# A31G324 register map
Vendor: ABOV Semiconductor Co., Ltd.; Series: A31G324; File version: 1.0
CPU: CM0PLUS r0p1, little endian, no MPU, no FPU, VTOR, 2 interrupt priority bits
Registers are 32-bit, read-write, reset 0x0 unless marked. A register's access mark holds for its fields unless they carry their own. Offsets are from the block's base; [hi:lo] are bit positions; {n}, {i} and the like mark numbered series.

## SCU — System Control Unit
Base 0x40000000
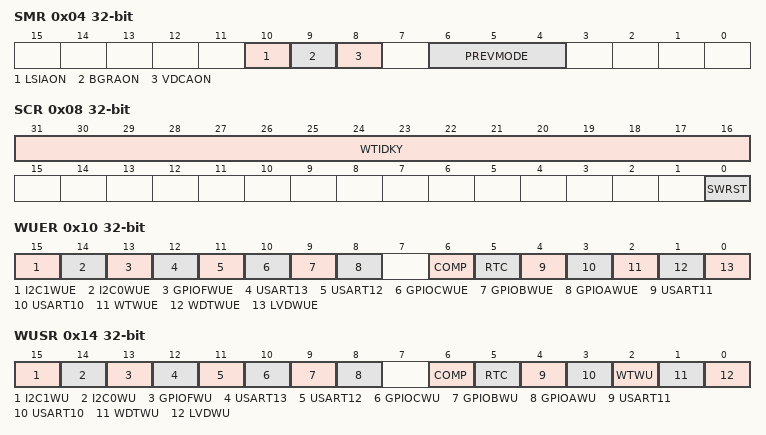
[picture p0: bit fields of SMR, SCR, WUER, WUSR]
0x04 SMR — System Mode Register
  [10] LSIAON — LSI Always on select bit in power down mode 0: LSI is automatically off entering power down mode 1: LSI isn't automatically off entering power down mode
  [9] BGRAON — BGR Always on select bit in power down mode 0: BGR is automatically off entering power down mode 1: BGR isn't automatically off entering power down mode
  [8] VDCAON — VDC Always on select bit in power down mode 0: VDC is automatically off entering power down mode 1: VDC isn't automatically off entering power down mdoe
  [6:4] PREVMODE — Previous operating mode before current reset event
0x08 SCR — System Control Register
  [31:16] WTIDKY wo — On writes, write 0x9EB3 to these bits, otherwise the write is ignored.
  [0] SWRST — Internal soft reset activation bit (check RSER[4] for reset)
0x10 WUER — Wake up source enable register
  [15] I2C1WUE — Enable wakeup source of I2C1 change event
  [14] I2C0WUE — Enable wakeup source of I2C0 change event
  [13] GPIOFWUE — Enable wakeup source of GPIOF port pin change event
  [12] USART13 — Enable wakeup source of USART13 change event
  [11] USART12 — Enable wakeup source of USART12 change event
  [10] GPIOCWUE — Enable wakeup source of GPIOC port pin change event
  [9] GPIOBWUE — Enable wakeup source of GPIOB port pin change event
  [8] GPIOAWUE — Enable wakeup source of GPIOA port pin change event
  [6] COMP — Enable wakeup source of COMP change event
  [5] RTC — Enable wakeup source of RTC change event
  [4] USART11 — Enable wakeup source of USART11 change event
  [3] USART10 — Enable wakeup source of USART10 change event
  [2] WTWUE — Enable wakeup source of watch timer event
  [1] WDTWUE — Enable wakeup source of watchdog timer event
  [0] LVDWUE — Enable wakeup source of LVD event
0x14 WUSR — Wake up source status register
  [15] I2C1WU ro — Status of wakeup source of I2C1 change event
  [14] I2C0WU ro — Status of wakeup source of I2C0 change event
  [13] GPIOFWU ro — Status of wakeup source of GPIOF port pin change event
  [12] USART13 ro — Status of wakeup source of USART13 change event
  [11] USART12 ro — Status of wakeup source of USART12 change event
  [10] GPIOCWU ro — Status of wakeup source of GPIOC port pin change event
  [9] GPIOBWU ro — Status of wakeup source of GPIOB port pin change event
  [8] GPIOAWU ro — Status of wakeup source of GPIOA port pin change event
  [6] COMP ro — Status of wakeup source of COMP change event
  [5] RTC ro — Status of wakeup source of RTC change event
  [4] USART11 ro — Status of wakeup source of USART11 change event
  [3] USART10 ro — Status of wakeup source of USART10 change event
  [2] WTWU ro — Status of wakeup source of watch timer event
  [1] WDTWU ro — Status of wakeup source of watchdog timer event
  [0] LVDWU ro — Status of wakeup source of LVD event
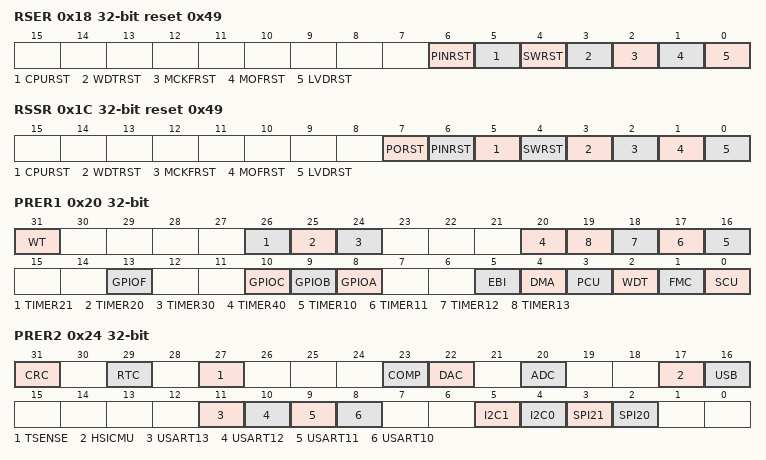
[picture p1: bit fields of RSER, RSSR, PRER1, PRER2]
0x18 RSER reset 0x49 — Reset source enable register
  [6] PINRST — External pin reset enable bit
  [5] CPURST — CPU request reset enable bit
  [4] SWRST — Software reset enable bit
  [3] WDTRST — Watchdog Timer reset enable bit
  [2] MCKFRST — MCLK Clock fail reset enable bit
  [1] MOFRST — MOSC Clock fail reset enable bit
  [0] LVDRST — LVD reset enable bit
0x1C RSSR reset 0x49 — Reset source status register
  [7] PORST — Power on reset status bit
  [6] PINRST — External pin reset status bit
  [5] CPURST — CPU request reset status bit
  [4] SWRST — Software reset status bit
  [3] WDTRST — Watchdog Timer reset status bit
  [2] MCKFRST — MCLK Clock fail reset status bit
  [1] MOFRST — MOSC Clock fail reset status bit
  [0] LVDRST — LVD reset status bit
0x20 PRER1 — Peripheral reset enable register 1
  [31] WT — WT reset mask
  [26] TIMER21 — TIMER21 reset mask
  [25] TIMER20 — TIMER20 reset mask
  [24] TIMER30 — TIMER30 reset mask
  [20] TIMER40 — TIMER40 reset mask
  [n+6] TIMER{n} (n=10..13) — TIMER{n} reset mask
  [13] GPIOF — GPIOF reset mask
  [10] GPIOC — GPIOC reset mask
  [9] GPIOB — GPIOB reset mask
  [8] GPIOA — GPIOA reset mask
  [5] EBI — EBI reset mask
  [4] DMA — DMA reset mask
  [3] PCU — PCU reset mask
  [2] WDT — WDT reset mask
  [1] FMC — FMC reset mask
  [0] SCU — SCU reset mask
0x24 PRER2 — Peripheral reset enable register 2
  [31] CRC — CRC reset mask
  [29] RTC — RTC reset mask
  [27] TSENSE — TSENSE reset mask
  [23] COMP — COMP reset mask
  [22] DAC — DAC reset mask
  [20] ADC — ADC reset mask
  [17] HSICMU — HSICMU reset mask
  [16] USB — USB reset mask
  [11] USART13 — USART13 reset mask
  [10] USART12 — UASRT12 reset mask
  [9] USART11 — USART11 reset mask
  [8] USART10 — USART10 reset mask
  [5] I2C1 — I2C1 reset mask
  [4] I2C0 — I2C0 reset mask
  [3] SPI21 — SPI21 reset mask
  [2] SPI20 — SPI20 reset mask
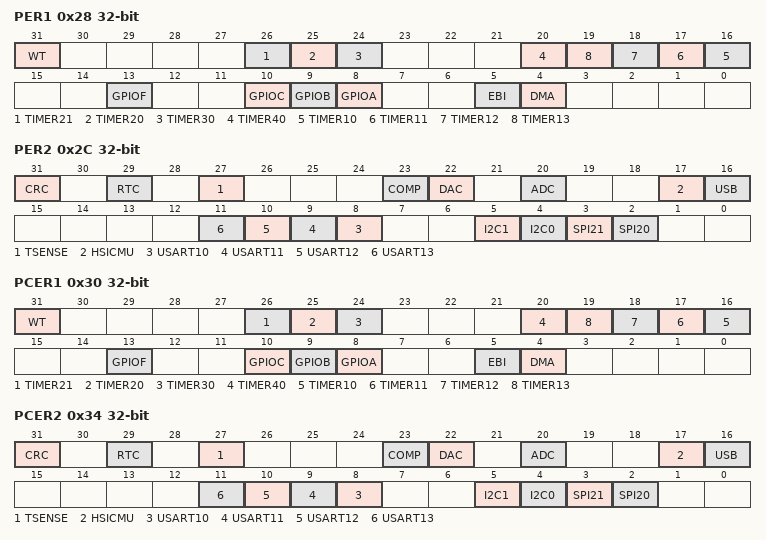
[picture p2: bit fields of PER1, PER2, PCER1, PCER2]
0x28 PER1 — Peripheral enable register 1
  [31] WT — WT function enable
  [26] TIMER21 — TIMER21 function enable
  [25] TIMER20 — TIMER20 function enable
  [24] TIMER30 — TIMER30 function enable
  [20] TIMER40 — TIMER40 function enable
  [n+6] TIMER{n} (n=10..13) — TIMER{n} function enable
  [13] GPIOF — GPIOF function enable
  [10] GPIOC — GPIOC function enable
  [9] GPIOB — GPIOB function enable
  [8] GPIOA — GPIOA function enable
  [5] EBI — EBI function enable
  [4] DMA — DMA function enable
0x2C PER2 — Peripheral enable register 2
  [31] CRC — CRC function enable
  [29] RTC — RTC function enable
  [27] TSENSE — TSENSE function enable
  [23] COMP — COMP function enable
  [22] DAC — DAC function enable
  [20] ADC — ADC function enable
  [17] HSICMU — HSICMU function enable
  [16] USB — USB function enable
  [n-2] USART{n} (n=10..13) — USART{n} function enable
  [5] I2C1 — I2C1 function enable
  [4] I2C0 — I2C0 function enable
  [3] SPI21 — SPI21 function enable
  [2] SPI20 — SPI20 function enable
0x30 PCER1 — Peripheral clock enable register 1
  [31] WT — WT clock enable
  [26] TIMER21 — TIMER21 clock enable
  [25] TIMER20 — TIMER20 clock enable
  [24] TIMER30 — TIMER30 clock enable
  [20] TIMER40 — TIMER40 clock enable
  [n+6] TIMER{n} (n=10..13) — TIMER{n} clock enable
  [13] GPIOF — GPIOF clock enable
  [10] GPIOC — GPIOC clock enable
  [9] GPIOB — GPIOB clock enable
  [8] GPIOA — GPIOA clock enable
  [5] EBI — EBI clock enable
  [4] DMA — DMA clock enable
0x34 PCER2 — Peripheral clock enable register 2
  [31] CRC — CRC clock enable
  [29] RTC — RTC clock enable
  [27] TSENSE — TSENSE clock enable
  [23] COMP — COMP clock enable
  [22] DAC — DAC clock enable
  [20] ADC — ADC clock enable
  [17] HSICMU — HSICMU clock enable
  [16] USB — USB clock enable
  [n-2] USART{n} (n=10..13) — USART{n} clock enable
  [5] I2C1 — I2C1 clock enable
  [4] I2C0 — I2C0 clock enable
  [3] SPI21 — SPI21 clock enable
  [2] SPI20 — SPI20 clock enable
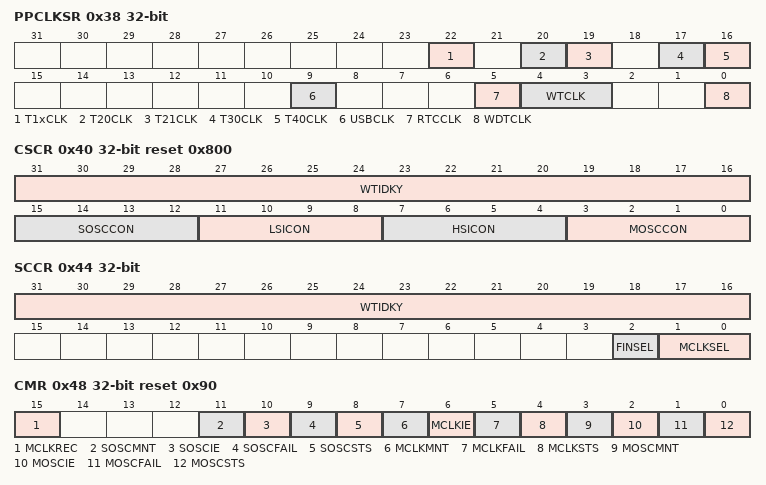
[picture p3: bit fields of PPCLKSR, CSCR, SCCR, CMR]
0x38 PPCLKSR — Peripheral clock selection register
  [22] T1xCLK — Timer 1x Clock Selection bit
  [20] T20CLK — Timer 20 Clock Selection bit
  [19] T21CLK — Timer 21 Clock Selection bit
  [17] T30CLK — Timer 30 Clock Selection bit
  [16] T40CLK — Timer 40 Clock Selection bit
  [9] USBCLK — USB Clock Selection bit
  [5] RTCCLK — RTC Clock Selection bit
  [4:3] WTCLK — Watch Timer Clock Selection bit Note) These bits should be changed during the WTEN bit of watch timer control register (WTCR) is "0b"
  [0] WDTCLK — Watch-dog Timer Clock Selection bit
0x40 CSCR reset 0x800 — Clock Source Control register
  [31:16] WTIDKY wo — On writes, write 0xA507 to these bits, otherwise the write is ignored.
  [15:12] SOSCCON — External crystal sub oscillator control
  [11:8] LSICON — Low speed internal oscillator control
  [7:4] HSICON — High speed internal oscillator control
  [3:0] MOSCCON — External crystal main oscillator control
0x44 SCCR — System Clock Control register
  [31:16] WTIDKY wo — On writes, write 0x570A to these bits, otherwise the write is ignored.
  [2] FINSEL — PLL input source FIN select register
  [1:0] MCLKSEL — System clock select register
0x48 CMR reset 0x90 — Clock Monitoring register
  [15] MCLKREC — MCLK fail auto recovery
  [11] SOSCMNT — External sub oscillator monitoring enable
  [10] SOSCIE — External sub oscillator fail interrupt enable
  [9] SOSCFAIL — External sub oscillator fail interrupt
  [8] SOSCSTS — External sub oscillator status
  [7] MCLKMNT — MCLK monitoring enable
  [6] MCLKIE — MCLK fail interrupt enable
  [5] MCLKFAIL — MCLK fail interrupt
  [4] MCLKSTS — MCLK clock status
  [3] MOSCMNT — External main oscillator monitoring enable
  [2] MOSCIE — External main oscillator fail interrupt enable
  [1] MOSCFAIL — External main oscillator fail interrupt
  [0] MOSCSTS — External main oscillator status
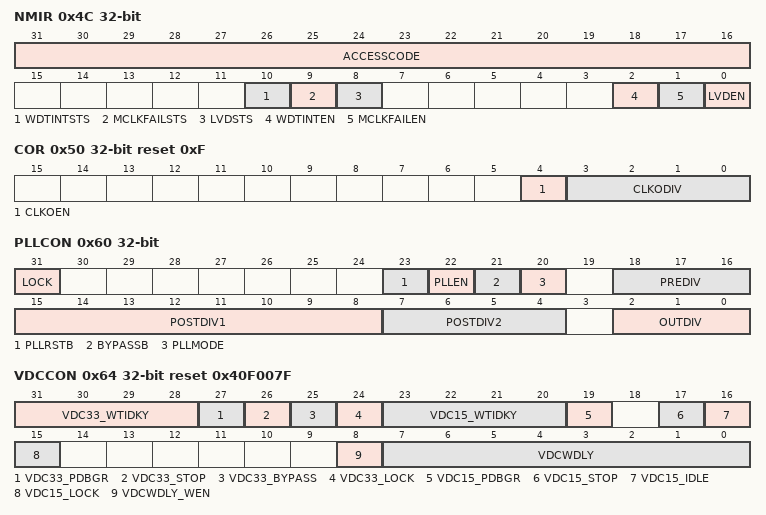
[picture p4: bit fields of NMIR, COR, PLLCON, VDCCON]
0x4C NMIR — NMI control register
  [31:16] ACCESSCODE wo — This field enables writing access to this register. Writing 0xA32C is to enable writing.
  [10] WDTINTSTS ro — WDT Interrupt condition status bit This bit can't invoke NMI interrupt without enable bit
  [9] MCLKFAILSTS ro — MCLK Fail condition status bit This bit can't invoke NMI interrupt without enable bit
  [8] LVDSTS ro — LVD condition status bit This bit can't invoke NMI interrupt without enable bit
  [2] WDTINTEN — WDT Interrupt condition enable for NMI interrupt
  [1] MCLKFAILEN — MCLK Fail condition enable for NMI interrupt
  [0] LVDEN — LVD Fail condition enable for NMI interrupt
0x50 COR reset 0xF — Clock Output Control register
  [4] CLKOEN — Clock output enable
  [3:0] CLKODIV — Clock output divider value CLKO=MCLK (CLKODIV=0) CLKO=MCLK/2(CLKODIV+1) (CLKODIV > 0)
0x60 PLLCON — PLL Control register
  [31] LOCK — LOCK status
  [23] PLLRSTB — PLL reset
  [22] PLLEN — PLL enable
  [21] BYPASSB — FIN bypass
  [20] PLLMODE — PLL VCO mode
  [18:16] PREDIV — FIN predivider FIN divided by (PREDIV + 1), (FIN/1 ~ FIN/8)
  [15:8] POSTDIV1 — Feedback control 1 (N1) N1 = POSTDIV1 + 1
  [7:4] POSTDIV2 — Feedback control 1 (N2) N2 = POSTDIV2 + 1
  [2:0] OUTDIV — output divider control (P) P = OUTDIV + 1
0x64 VDCCON reset 0x40F007F — VDC Control register
  [31:28] VDC33_WTIDKY wo — VDC33 Write Identification Key On writes, write 0xA to these bits, otherwise the write is ignored.
  [27] VDC33_PDBGR — VDC33 BGR Power Down Signal
  [26] VDC33_STOP — VDC33 STOP Mode Enable Signal
  [25] VDC33_BYPASS — VDC33 Bypass Mode Enable Signal
  [24] VDC33_LOCK — VDC33 VDC option write enable.
  [23:20] VDC15_WTIDKY wo — VDC15 Write Identification Key On writes, write 0x5 to these bits, otherwise the write is ignored.
  [19] VDC15_PDBGR — VDC15 1.2V BGR / 1.0V Buffer Power Down Signal *In BGR on off, VDCLOCK_I should be 0
  [17] VDC15_STOP — VDC15 STOP Mode Control Signal
  [16] VDC15_IDLE — VDC15 STOP1 Mode Control Signal
  [15] VDC15_LOCK — VDC15 VDCLOCK Control Signal for *BGR Stabilization *In BGR off on Sequence, VDCLOCK_I should be 0 during 120usec
  [8] VDCWDLY_WEN wo — VDCWDLY value write enable. VDCWDLY value can be written with writing '1' to VDCWDLY_WEN bit simultaneously.
  [7:0] VDCWDLY — VDC warm-up delay count value. When SCU is waked up from powerdown mode, the warm-up delay is inserted for VDC output being stabilized. The amount of delay can be defined with this register value 7F : 4msec
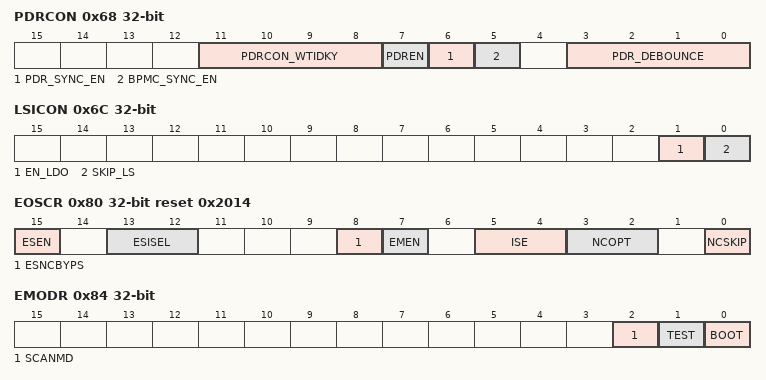
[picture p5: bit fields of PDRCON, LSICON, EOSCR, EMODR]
0x68 PDRCON — PDR Control register
  [11:8] PDRCON_WTIDKY wo — PDRCON Write Identification Key On writes, write 0xA to these bits, otherwise the write is ignored.
  [7] PDREN — PDR ENABLE
  [6] PDR_SYNC_EN
  [5] BPMC_SYNC_EN
  [3:0] PDR_DEBOUNCE
0x6C LSICON — Low Speed Internal OSC Control Register
  [1] EN_LDO — Internal LDO On/Off
  [0] SKIP_LS — Internal Level Shifter control signal
0x80 EOSCR reset 0x2014 — External Oscillator control register
  [15] ESEN wo — Write enable for External SOSC
  [13:12] ESISEL — Internal Level Shifter control signal
  [8] ESNCBYPS — Noise Cancel Bypass enable for External SOSC
  [7] EMEN wo — Write enable for External MOSC
  [5:4] ISE — Select current for External MOSC
  [3:2] NCOPT — Noise Cancel delay Option for External MOSC
  [0] NCSKIP — Noise Cancel Bypass enable for External SOSC
0x84 EMODR — External mode pin read register
  [2] SCANMD ro — SCAN Mode level
  [1] TEST ro — TEST Mode level
  [0] BOOT ro — BOOT pin level
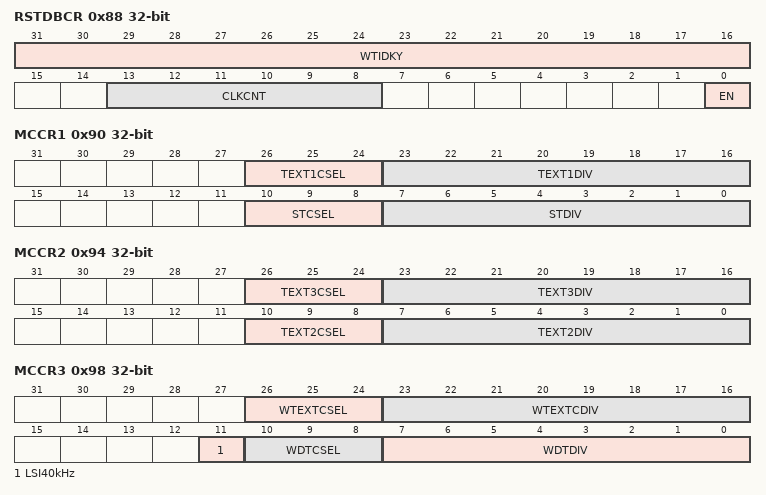
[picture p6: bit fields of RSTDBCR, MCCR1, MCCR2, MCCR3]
0x88 RSTDBCR — Pin Reset Debounce Control register
  [31:16] WTIDKY wo — Write Identification Key
  [13:8] CLKCNT — Noise Cancel delay Option for External MOSC
  [0] EN — Pin reset debounce enable bit
0x90 MCCR1 — Miscellaneous Clock Control Register 1
  [26:24] TEXT1CSEL — TIMER1n EXT Clock source select bit
  [23:16] TEXT1DIV — TIMER1n EXT Clock N divider To change the value, set 0x0 first without changing TEXT1CSEL
  [10:8] STCSEL — systick clock source sel
  [7:0] STDIV — SYSTICK Clock N divider To change the value, set 0x0 first without changing STCSEL
0x94 MCCR2 — Miscellaneous Clock Control Register 2
  [26:24] TEXT3CSEL — TIMER 30 EXT Clock source select bit
  [23:16] TEXT3DIV — TIMER 30 EXT Clock N divider To change the value, set 0x0 first without changing TEXT3DIV
  [10:8] TEXT2CSEL
  [7:0] TEXT2DIV — TIMER 20 EXT Clock N divider To change the value, set 0x0 first without changing TEXT2CSEL
0x98 MCCR3 — Miscellaneous Clock Control Register 3
  [26:24] WTEXTCSEL
  [23:16] WTEXTCDIV — WT External Clock N divider To change the value, set 0x0 first without changing WTEXTCSEL
  [11] LSI40kHz — LSI40kHz Enable
  [10:8] WDTCSEL — WDT clock sel
  [7:0] WDTDIV — WDT Clock N divider To change the value, set 0x0 first without changing WDTCSEL
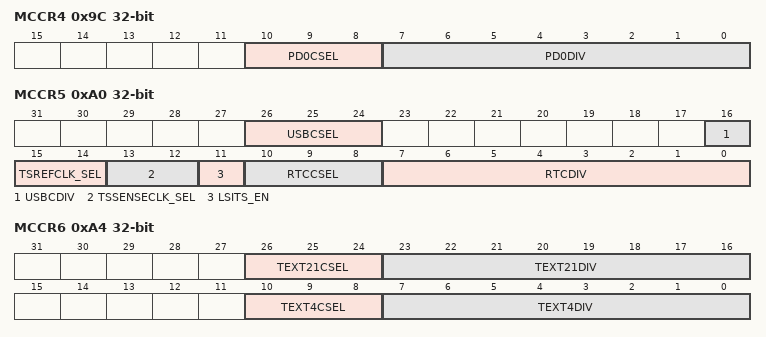
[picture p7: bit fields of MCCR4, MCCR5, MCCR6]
0x9C MCCR4 — Miscellaneous Clock Control Register 4
  [10:8] PD0CSEL — Debounce Clock for PORT source select bit (PA,PB,PC,PF)
  [7:0] PD0DIV — PORT Debounce Clock N divider (PA,PB,PC,PF) To change the value, set 0x0 first without changing PD0CSEL
0xA0 MCCR5 — Miscellaneous Clock Control Register 5
  [26:24] USBCSEL — USB Clock source select bit
  [16] USBCDIV — USB Clock N divider To change the value, set 0x0 first without changing USBCSEL
  [15:14] TSREFCLK_SEL — Temp Sensor Reference clock select bit Note) When reference clock is sub-osc reference and sense clock are changed to each other.
  [13:12] TSSENSECLK_SEL — Temp Sensor Sense clock select bit
  [11] LSITS_EN — LSITS Enable
  [10:8] RTCCSEL — Debounce Clock for RTC
  [7:0] RTCDIV — RTC Clock N divider
0xA4 MCCR6 — Miscellaneous Clock Control Register 6
  [26:24] TEXT21CSEL — TIMER 21 EXT Clock source select bit
  [23:16] TEXT21DIV — TIMER 21 EXT Clock N divider To change the value, set 0x0 first without changing TEXT2DIV
  [10:8] TEXT4CSEL — TIMER 40 EXT Clock source select bit
  [7:0] TEXT4DIV — TIMER 40 EXT Clock N divider To change the value, set 0x0 first without changing TEXT40CSEL
